# STM32H563xx register map
File version: 1.0
Registers are 32-bit, read-write, reset 0x0 unless marked. A register's access mark holds for its fields unless they carry their own. Offsets are from the block's base; [hi:lo] are bit positions; {n}, {i} and the like mark numbered series; 'fields as' and 'values as' point back to an identical list.

## DBGMCU — Debug MCU
Base 0x44024000
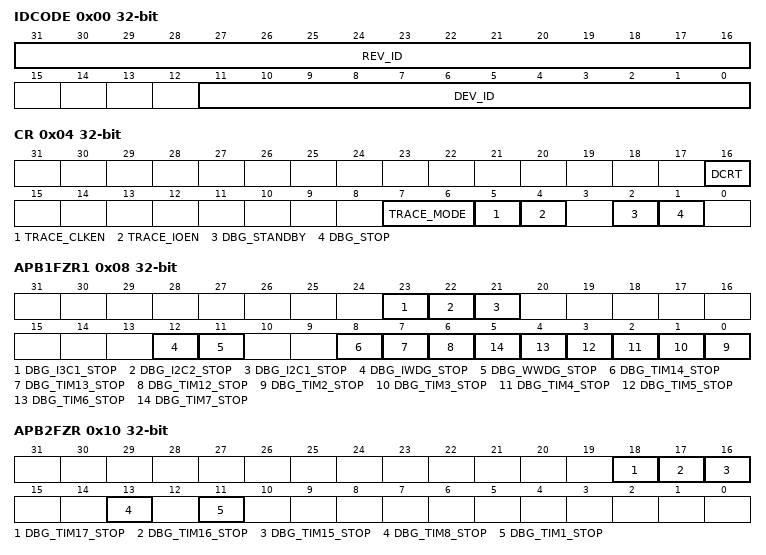
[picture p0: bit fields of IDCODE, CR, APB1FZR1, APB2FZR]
0x00 IDCODE — MCU device ID code
  [31:16] REV_ID, [11:0] DEV_ID
0x04 CR — Debug MCU configuration register
  [16] DCRT, [7:6] TRACE_MODE, [5] TRACE_CLKEN, [4] TRACE_IOEN, [2] DBG_STANDBY, [1] DBG_STOP
0x08 APB1FZR1 — Debug MCU APB1 freeze register 1
  [23] DBG_I3C1_STOP, [22] DBG_I2C2_STOP, [21] DBG_I2C1_STOP, [12] DBG_IWDG_STOP, [11] DBG_WWDG_STOP, [8] DBG_TIM14_STOP, [7] DBG_TIM13_STOP, [6] DBG_TIM12_STOP, [n-2] DBG_TIM{n}_STOP (n=2..7)
0x0C APB1FZR2 — Debug MCU APB1 freeze register 2
  [5] DBG_LPTIM2_STOP
0x10 APB2FZR — Debug MCU APB2 freeze register
  [18] DBG_TIM17_STOP, [17] DBG_TIM16_STOP, [16] DBG_TIM15_STOP, [13] DBG_TIM8_STOP, [11] DBG_TIM1_STOP
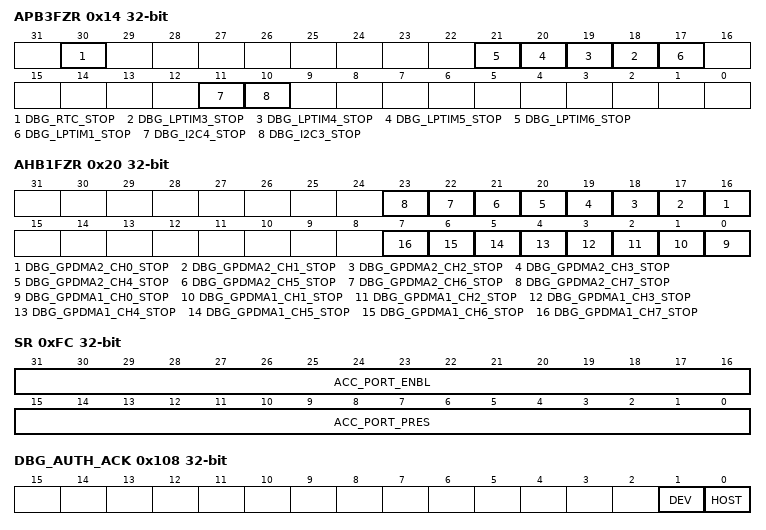
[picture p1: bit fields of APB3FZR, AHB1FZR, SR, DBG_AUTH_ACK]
0x14 APB3FZR — Debug MCU APB3 freeze register
  [30] DBG_RTC_STOP, [n+15] DBG_LPTIM{n}_STOP (n=3..6), [17] DBG_LPTIM1_STOP, [11] DBG_I2C4_STOP, [10] DBG_I2C3_STOP
0x20 AHB1FZR — Debug MCU AHB1 freeze register
  [n+16] DBG_GPDMA2_CH{n}_STOP (n=0..7), [n] DBG_GPDMA1_CH{n}_STOP (n=0..7)
0xFC SR — Debug MCU SR register
  [31:16] ACC_PORT_ENBL, [15:0] ACC_PORT_PRES
0x100 DBG_AUTH_HOST — Debug DBG_AUTH_HOST register
0x104 DBG_AUTH_DEV — Debug DBG_AUTH_DEV register
0x108 DBG_AUTH_ACK — Debug DBG_AUTH_ACK register
  [1] DEV, [0] HOST
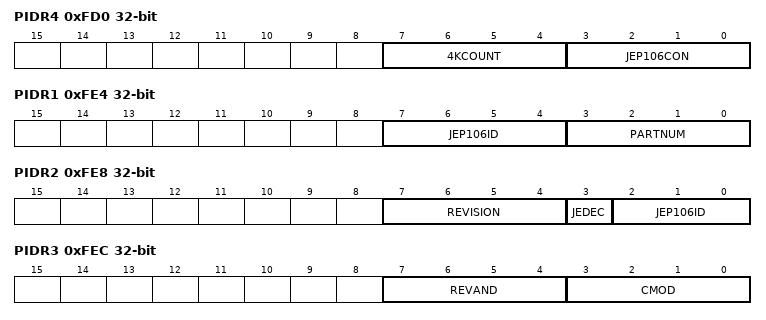
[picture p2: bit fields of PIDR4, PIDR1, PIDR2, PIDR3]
0xFD0 PIDR4 — Debug MCU Peripheral ID register 4
  [7:4] 4KCOUNT, [3:0] JEP106CON
{0xFC0+4i} PIDR{i} (i=5..7) — Debug MCU Peripheral ID register {i}
0xFE0 PIDR0 — Debug MCU Peripheral ID register 0
  [7:0] PARTNUM
0xFE4 PIDR1 — Debug MCU Peripheral ID register 1
  [7:4] JEP106ID, [3:0] PARTNUM
0xFE8 PIDR2 — Debug MCU Peripheral ID register 2
  [7:4] REVISION, [3] JEDEC, [2:0] JEP106ID
0xFEC PIDR3 — Debug MCU Peripheral ID register 3
  [7:4] REVAND, [3:0] CMOD
0xFF0 CIDR0 — Debug MCU Component ID register 0
  [7:0] PREAMBLE
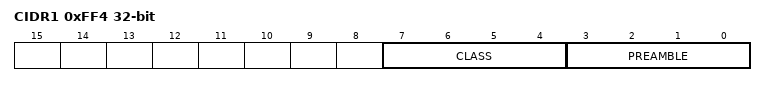
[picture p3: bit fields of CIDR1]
0xFF4 CIDR1 — Debug MCU Component ID register 1
  [7:4] CLASS, [3:0] PREAMBLE
0xFF8 CIDR2 — Debug MCU Component ID register 2
  [7:0] PREAMBLE
0xFFC CIDR3 — Debug MCU Component ID register 3
  [7:0] PREAMBLE

## DLYB_SDMMC1 — Delay Block DLYB
Base 0x46008400
Same registers: DLYB_SDMMC2 0x46008800, DLYB_OCTOSPI1 0x4600F000, DLYB_SDMMC1_S 0x56008400, DLYB_SDMMC2_S 0x56008800, DLYB_OCTOSPI1_S 0x5600F000
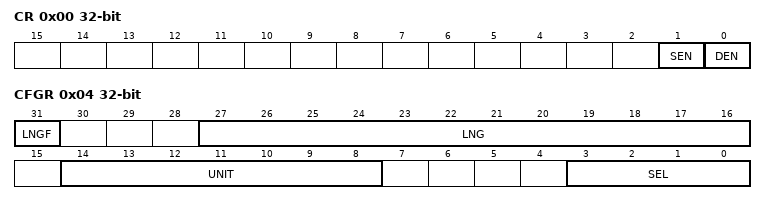
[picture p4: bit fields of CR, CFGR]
0x00 CR — DELAY BLOCK control register
  [1] SEN — Sampler length enable
  [0] DEN — Delay Block enable
0x04 CFGR — DELAY BLOCK configuration register
  [31] LNGF — Length valid flag
  [27:16] LNG — Delay line length value[11:0]
  [14:8] UNIT — Delay Defines the delay of a Unit delay cell[6:0]
  [3:0] SEL — Select the phase for the Output clock[3:0]

## FMC_Bank1_R — Flexible Memory Controller
Base 0x47000400
Same registers: FMC_Bank1_R_S 0x57000400
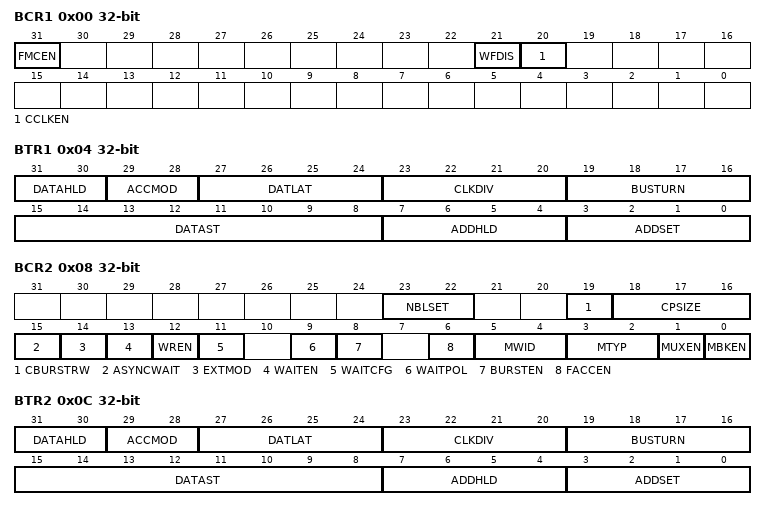
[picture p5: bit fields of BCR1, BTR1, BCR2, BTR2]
0x00 BCR1 — NOR/PSRAM chip-select control register(BCR) and chip-select timing register(BTR)
  [31] FMCEN — FMC controller Enable
  [21] WFDIS — Write FIFO Disable
  [20] CCLKEN — Continuous clock enable
0x04 BTR1 — NOR/PSRAM chip-select control register(BCR) and chip-select timing register(BTR)
  [31:30] DATAHLD — DATAHLD[1:0] bits (Data hold phase duration)
  [29:28] ACCMOD — ACCMOD[1:0] bits (Access mode)
  [27:24] DATLAT — DATLA[3:0] bits (Data latency)
  [23:20] CLKDIV — CLKDIV[3:0] bits (Clock divide ratio)
  [19:16] BUSTURN — BUSTURN[3:0] bits (Bus turnaround phase duration)
  [15:8] DATAST — DATAST [3:0] bits (Data-phase duration)
  [7:4] ADDHLD — ADDHLD[3:0] bits (Address-hold phase duration)
  [3:0] ADDSET — ADDSET[3:0] bits (Address setup phase duration)
0x08 BCR2 — NOR/PSRAM chip-select control register(BCR) and chip-select timing register(BTR)
  [23:22] NBLSET — Byte lane (NBL) setup
  [19] CBURSTRW — Write burst enable
  [18:16] CPSIZE — PSIZE[2:0] bits CRAM Page Size
  [15] ASYNCWAIT — Asynchronous wait
  [14] EXTMOD — Extended mode enable
  [13] WAITEN — Wait enable bit
  [12] WREN — Write enable bit
  [11] WAITCFG — Wait timing configuration
  [9] WAITPOL — Wait signal polarity bit
  [8] BURSTEN — Burst enable bit
  [6] FACCEN — Flash access enable
  [5:4] MWID — MWID[1:0] bits (Memory data bus width)
  [3:2] MTYP — MTYP[1:0] bits (Memory type)
  [1] MUXEN — Address/data multiplexing enable bit
  [0] MBKEN — Memory bank enable bit
0x0C BTR2 — NOR/PSRAM chip-select control register(BCR) and chip-select timing register(BTR)
  fields as BTR1
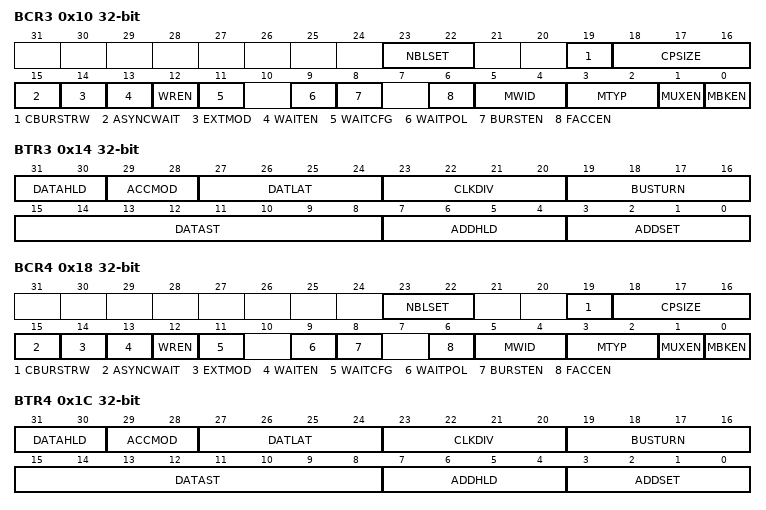
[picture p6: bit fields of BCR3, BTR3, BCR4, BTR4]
0x10 BCR3 — NOR/PSRAM chip-select control register(BCR) and chip-select timing register(BTR)
  fields as BCR2
0x14 BTR3 — NOR/PSRAM chip-select control register(BCR) and chip-select timing register(BTR)
  fields as BTR1
0x18 BCR4 — NOR/PSRAM chip-select control register(BCR) and chip-select timing register(BTR)
  fields as BCR2
0x1C BTR4 — NOR/PSRAM chip-select control register(BCR) and chip-select timing register(BTR)
  fields as BTR1
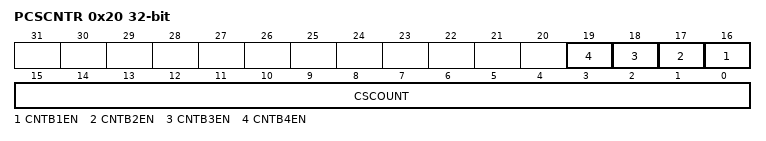
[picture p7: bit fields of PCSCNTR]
0x20 PCSCNTR — PSRAM chip-select counter register
  [n+15] CNTB{n}EN (n=1..4) — Counter PSRAM/NOR Bank1_{n} enable
  [15:0] CSCOUNT — CSCOUNT[15:0] bits (Chip select counter)
